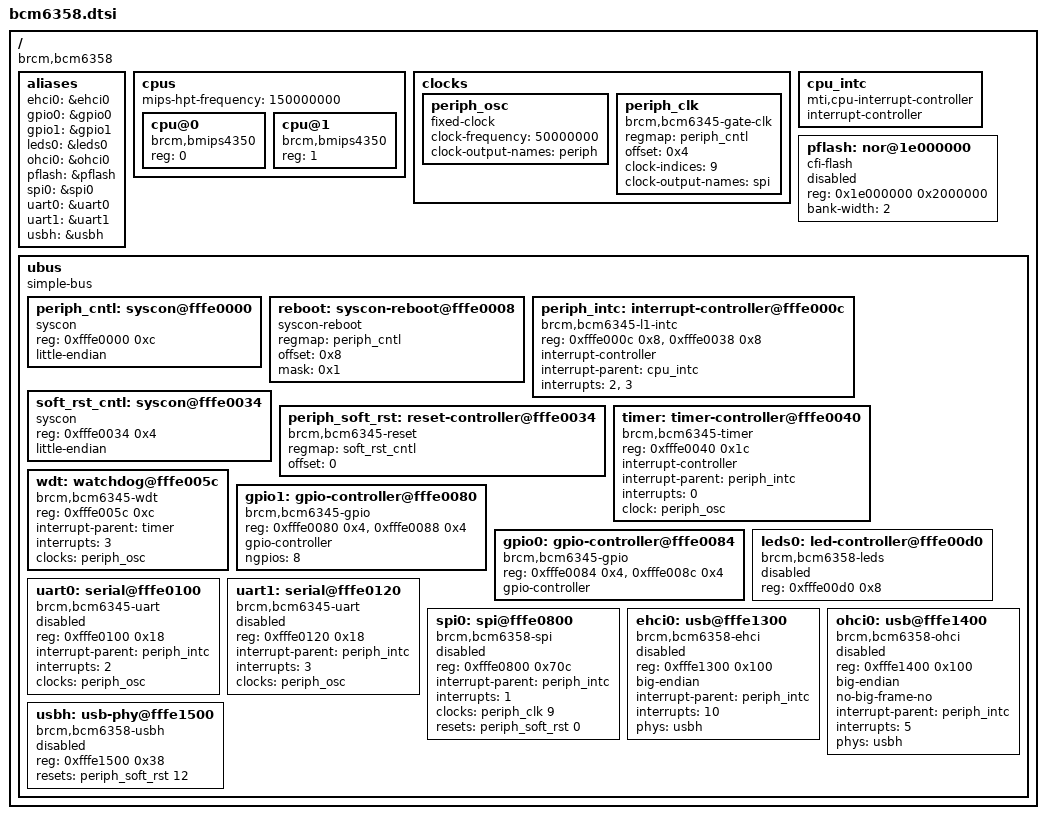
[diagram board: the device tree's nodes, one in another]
#include <dt-bindings/gpio/gpio.h>
#include <dt-bindings/input/input.h>

/ {
	#address-cells = <1>;
	#size-cells = <1>;
	compatible = "brcm,bcm6358";

	aliases {
		ehci0 = &ehci0;
		gpio0 = &gpio0;
		gpio1 = &gpio1;
		leds0 = &leds0;
		ohci0 = &ohci0;
		pflash = &pflash;
		spi0 = &spi0;
		uart0 = &uart0;
		uart1 = &uart1;
		usbh = &usbh;
	};

	cpus {
		#address-cells = <1>;
		#size-cells = <0>;
		mips-hpt-frequency = <150000000>;

		cpu@0 {
			compatible = "brcm,bmips4350", "mips,mips4Kc";
			device_type = "cpu";
			reg = <0>;
		};
		cpu@1 {
			compatible = "brcm,bmips4350", "mips,mips4Kc";
			device_type = "cpu";
			reg = <1>;
		};
	};

	clocks {
		periph_osc: periph_osc {
			compatible = "fixed-clock";

			#clock-cells = <0>;

			clock-frequency = <50000000>;
			clock-output-names = "periph";
		};

		periph_clk: periph_clk {
			compatible = "brcm,bcm6345-gate-clk";
			regmap = <&periph_cntl>;
			offset = <0x4>;

			/*
			 4: enet
			 5: adsl
			 8: pcm
			 9: spi
			 10: usbs
			 11: sar
			 17: emusb
			 18: enet0
			 19: enet1
			 20: usbsu
			 21: ephy
			*/

			#clock-cells = <1>;

			clock-indices = <9>;
			clock-output-names = "spi";
		};
	};

	cpu_intc: cpu_intc {
		#address-cells = <0>;
		compatible = "mti,cpu-interrupt-controller";

		interrupt-controller;
		#interrupt-cells = <1>;
	};

	pflash: nor@1e000000 {
		#address-cells = <1>;
		#size-cells = <1>;
		compatible = "cfi-flash";
		reg = <0x1e000000 0x2000000>;
		bank-width = <2>;

		status = "disabled";
	};

	ubus {
		#address-cells = <1>;
		#size-cells = <1>;

		compatible = "simple-bus";
		ranges;

		periph_cntl: syscon@fffe0000 {
			compatible = "syscon";
			reg = <0xfffe0000 0xc>;
			little-endian;
		};

		reboot: syscon-reboot@fffe0008 {
			compatible = "syscon-reboot";
			regmap = <&periph_cntl>;
			offset = <0x8>;
			mask = <0x1>;
		};

		periph_intc: interrupt-controller@fffe000c {
			compatible = "brcm,bcm6345-l1-intc";
			reg = <0xfffe000c 0x8>,
			      <0xfffe0038 0x8>;

			interrupt-controller;
			#interrupt-cells = <1>;

			interrupt-parent = <&cpu_intc>;
			interrupts = <2>, <3>;
		};

		soft_rst_cntl: syscon@fffe0034 {
			compatible = "syscon";
			reg = <0xfffe0034 0x4>;
			little-endian;
		};

		periph_soft_rst: reset-controller@fffe0034 {
			compatible = "brcm,bcm6345-reset";
			regmap = <&soft_rst_cntl>;
			offset = <0>;

			#reset-cells = <1>;

			/*
			 0: spi
			 2: emac
			 3: mpi
			 5: fpm
			 6: ephy
			 7: sar
			 12: usbh
			 13: pcm
			 14: adsl
			*/
		};

		timer: timer-controller@fffe0040 {
			compatible = "brcm,bcm6345-timer";
			reg = <0xfffe0040 0x1c>;

			interrupt-controller;
			#interrupt-cells = <1>;

			interrupt-parent = <&periph_intc>;
			interrupts = <0>;

			clock = <&periph_osc>;
		};

		wdt: watchdog@fffe005c {
			compatible = "brcm,bcm6345-wdt";
			reg = <0xfffe005c 0xc>;

			interrupt-parent = <&timer>;
			interrupts = <3>;

			clocks = <&periph_osc>;
		};

		gpio1: gpio-controller@fffe0080 {
			compatible = "brcm,bcm6345-gpio";
			reg = <0xfffe0080 0x4>, <0xfffe0088 0x4>;

			gpio-controller;
			#gpio-cells = <2>;

			ngpios = <8>;
		};

		gpio0: gpio-controller@fffe0084 {
			compatible = "brcm,bcm6345-gpio";
			reg = <0xfffe0084 0x4>, <0xfffe008c 0x4>;

			gpio-controller;
			#gpio-cells = <2>;
		};

		leds0: led-controller@fffe00d0 {
			#address-cells = <1>;
			#size-cells = <0>;
			compatible = "brcm,bcm6358-leds";
			reg = <0xfffe00d0 0x8>;

			status = "disabled";
		};

		uart0: serial@fffe0100 {
			compatible = "brcm,bcm6345-uart";
			reg = <0xfffe0100 0x18>;

			interrupt-parent = <&periph_intc>;
			interrupts = <2>;

			clocks = <&periph_osc>;

			status = "disabled";
		};

		uart1: serial@fffe0120 {
			compatible = "brcm,bcm6345-uart";
			reg = <0xfffe0120 0x18>;

			interrupt-parent = <&periph_intc>;
			interrupts = <3>;

			clocks = <&periph_osc>;

			status = "disabled";
		};

		spi0: spi@fffe0800 {
			compatible = "brcm,bcm6358-spi";
			reg = <0xfffe0800 0x70c>;
			#address-cells = <1>;
			#size-cells = <1>;

			interrupt-parent = <&periph_intc>;
			interrupts = <1>;

			clocks = <&periph_clk 9>;
			clock-names = "spi";

			resets = <&periph_soft_rst 0>;

			status = "disabled";
		};

		ehci0: usb@fffe1300 {
			compatible = "brcm,bcm6358-ehci", "generic-ehci";
			reg = <0xfffe1300 0x100>;
			big-endian;

			interrupt-parent = <&periph_intc>;
			interrupts = <10>;

			phys = <&usbh>;

			status = "disabled";
		};

		ohci0: usb@fffe1400 {
			compatible = "brcm,bcm6358-ohci", "generic-ohci";
			reg = <0xfffe1400 0x100>;
			big-endian;
			no-big-frame-no;

			interrupt-parent = <&periph_intc>;
			interrupts = <5>;

			phys = <&usbh>;

			status = "disabled";
		};

		usbh: usb-phy@fffe1500 {
			compatible = "brcm,bcm6358-usbh";
			reg = <0xfffe1500 0x38>;

			#phy-cells = <0>;

			resets = <&periph_soft_rst 12>;

			status = "disabled";
		};
	};
};
